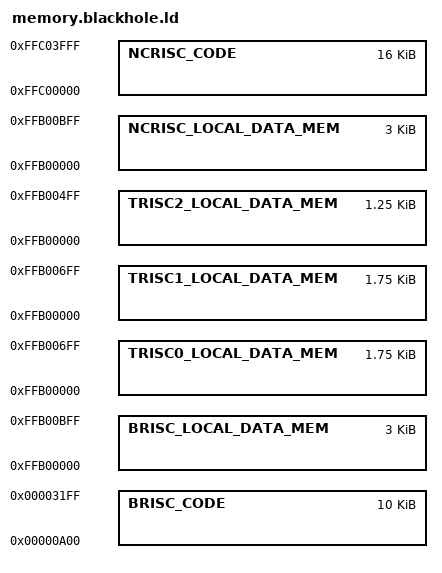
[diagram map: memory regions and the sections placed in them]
MEMORY
{
    BRISC_LOCAL_DATA_MEM : ORIGIN = 0xFFB00000, LENGTH = (4 * 1024) - 1024
    TRISC0_LOCAL_DATA_MEM : ORIGIN = 0xFFB00000, LENGTH = (2 * 1024) - 256
    TRISC1_LOCAL_DATA_MEM : ORIGIN = 0xFFB00000, LENGTH = (2 * 1024) - 256
    TRISC2_LOCAL_DATA_MEM : ORIGIN = 0xFFB00000, LENGTH = (2 * 1024) - 768
    NCRISC_LOCAL_DATA_MEM : ORIGIN = 0xFFB00000, LENGTH = (4 * 1024) - 1024
    BRISC_STACK_MEM : ORIGIN = (0xFFB00000 + (4 * 1024) - 1024), LENGTH = 1024
    TRISC0_STACK_MEM : ORIGIN = (0xFFB00000 + (2 * 1024) - 256), LENGTH = 256
    TRISC1_STACK_MEM : ORIGIN = (0xFFB00000 + (2 * 1024) - 256), LENGTH = 256
    TRISC2_STACK_MEM : ORIGIN = (0xFFB00000 + (2 * 1024) - 768), LENGTH = 768
    NCRISC_STACK_MEM : ORIGIN = (0xFFB00000 + (4 * 1024) - 1024), LENGTH = 1024
    BRISC_CODE : ORIGIN = (2048 + 512), LENGTH = (10 * 1024)
    TRISC0_CODE : ORIGIN = ((2048 + 512) + (10 * 1024)), LENGTH = (16 * 1024)
    TRISC1_CODE : ORIGIN = (((2048 + 512) + (10 * 1024)) + (16 * 1024)), LENGTH = (16 * 1024)
    TRISC2_CODE : ORIGIN = ((((2048 + 512) + (10 * 1024)) + (16 * 1024)) + (16 * 1024)), LENGTH = (16 * 1024)
    NCRISC_CODE : ORIGIN = 0xFFC00000, LENGTH = (16 * 1024)
}
